# NUC400_v1 register map
File version: 1.0
Registers are 32-bit, read-write, reset 0x0 unless marked. A register's access mark holds for its fields unless they carry their own. Offsets are from the block's base; [hi:lo] are bit positions; {n}, {i} and the like mark numbered series.

## PDMA — PDMA Register Map
Base 0x40008000
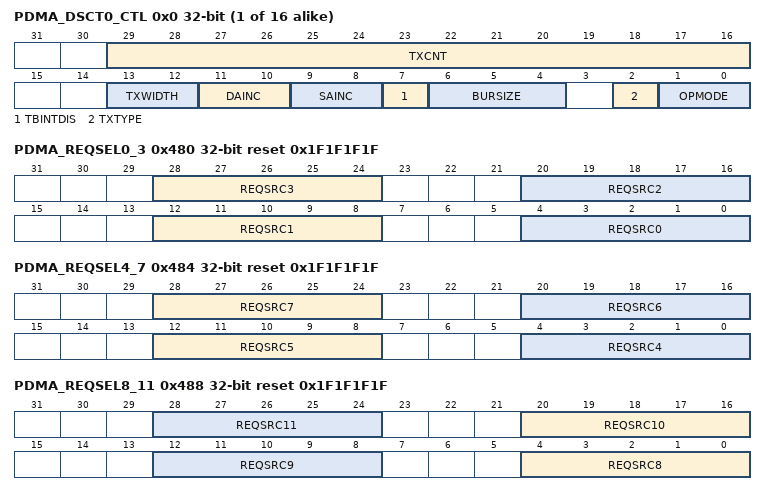
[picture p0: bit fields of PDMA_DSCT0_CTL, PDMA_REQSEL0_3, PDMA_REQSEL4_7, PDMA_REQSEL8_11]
{0x0+0x10*i} PDMA_DSCT{i}_CTL reset not defined (i=0..15) — Descriptor Table Control Register of PDMA Channel {i}
  [29:16] TXCNT — Transfer Count. The TXCNT represents the required number of PDMA transfer, the real transfer count is (TXCNT + 1); The maximum transfer count is 16384, every transfer may be byte, half-word or word that is dependent on TXWIDTH field. Note: When PDMA finish each transfer item, this field will be decrease imminently
  [13:12] TXWIDTH — Transfer Width Selection. This field is used for transfer width. Note: The PDMA transfer source address (DSCTx_ENDSA) and PDMA transfer destination address (DSCTx_ENDDA) should be alignment under the TXWIDTH selection
    0=8 bits for every transfer item; 1=16 bits for every transfer item; 2=32 bits for every transfer item
  [11:10] DAINC — Destination Address Increment. This field is used to set the destination address increment size
    3=No Increment (Fixed Address.)
  [9:8] SAINC — Source Address Increment. This field is used to set the source address increment size
    3=No Increment (Fixed Address.)
  [7] TBINTDIS — Table Interrupt Disable Bit. This field can be used to decide whether to enable table interrupt or not. When with transfer done flag, this bit is only used for scatter-gather mode. If the TBINTDIS bit is enabled when PDMA finishes this task, there will no interrupt generated. However, with the table empty flag, this bit is also useful. If it is set to '1", the TEMPTYF will not be set when this situation has happened.
    0=Table interrupt Enabled; 1=Table interrupt Disabled
  [6:4] BURSIZE — Burst Size. This field is used for peripheral to determine the burst size or used for determine the re-arbitration size. But if in Single Request Type, this field is not useful and only 1 transfer item been transmitted for each transfer
    0=128 transfers; 1=64 transfers; 2=32 transfers; 3=16 transfers; 4=8 transfers; 5=4 transfers; 6=2 transfers; 7=1 transfers
  [2] TXTYPE — Request Type
    0=Burst request type; 1=Single request type
  [1:0] OPMODE — PDMA Operation Mode Selection. Note: Before filling transfer task in the descriptor table, user must check if the descriptor table is complete.
    0=Stop Mode. Channel is stopped or this table is complete, when PDMA finish channel table task, OPMODE will be cleared to stop mode automatically; 1=Basic Mode. The descriptor table only has one task. When this task is finished, the PDMA_INTSTS[x] will be asserted; 2=Scatter-Gather Mode. When operating in this mode, user must give the next descriptor table address in DSCTx_NEXT register; PDMA will ignore this task, and then load the next task to execute
{0x4+0x10*i} PDMA_DSCT{i}_ENDSA reset not defined (i=0..15) — End Source Address Register of PDMA Channel {i}
  [31:0] ENDSA — PDMA Transfer Ending Source Address Bits. This field indicates a 32-bit ending source address of PDMA. Note: If the source start address is 0x2000_0000, the transfer count is 0x100 and the source address increment is word, this field must be filled 0x2000_0400.
{0x8+0x10*i} PDMA_DSCT{i}_ENDDA reset not defined (i=0..15) — End Destination Address Register of PDMA Channel {i}
  [31:0] ENDDA — PDMA Transfer Ending Destination Address Bits. This field indicates a 32-bit ending destination address of PDMA. Note: If the destination start address is 0x2000_0000, the transfer count is 0x100 and the destination address increment is word, this field must be filled 0x2000_0400.
{0xC+0x10*i} PDMA_DSCT{i}_NEXT reset not defined (i=0..15) — Scatter-gather Descriptor Table Offset Address of PDMA Channel {i}
  [15:2] NEXT — PDMA Next Description Table Offset Address Bits. This field indicates the offset of next descriptor table address in system memory. Note1: The next descriptor table address must be word boundary. Note2: The system memory based address is 0x2000_0000 (PDMA_SCATBA), if the next descriptor table is 0x2000_0100, that this field must fill 0x0100. Note3: Before filled transfer task in the description table, user must check if the descriptor table is complete.
{0x100+4i} PDMA_CURSCAT{i} ro (i=0..15) — Current Scatter-gather Descriptor Table Address of PDMA Channel {i}
  [31:0] CURADDR — PDMA External Current Descriptor Address Bits. This field indicates a 32-bit current external descriptor address of PDMA. Note: This field is read only and only used for Scatter-Gather mode to indicate the current external descriptor address.
0x400 PDMA_CHCTL — PDMA Channel Control Register
  [15:0] CHEN — PDMA Channel Enable Control Bit[X]. Set this bit to 1 to enable PDMA[x] operation. Note1: If software stops each PDMA transfer by setting PDMA_STOP register, this bit will be cleared automatically after finishing current transfer. Note2: Software reset (writing 0xFFFF_FFF to PDMA_STOP register) will clear this bit. Note3: If each channel is not set as enabled, each channel cannot be active.
    0=PDMA channel [x] Disabled; 1=PDMA channel [x] Enabled
0x404 PDMA_STOP wo — PDMA Stop Transfer Register
  [15:0] STOP — PDMA Stop Transfer Bit [X]. User can stop the PDMA transfer by software reset (writing all '1' to PDMA_STOP register) or by PDMA_STOP register. The difference between software reset and PDMA_STOP register is when software set software reset, the operation will be stopped imminently that include the on-going transfer and the channel enable bit and request active flag will be cleared to '0'. When software set PDMA_STOP bit, the operation will finish the on-going transfer channel and then clear the channel enable bit and request active flag. Software can poll channel enable bit to know if the on-going transfer is finished. Note1: This field is Write-Only; Note2: Setting all PDMA_STOP bit to "1" will generate software reset to reset internal state machine (the embedded table will not be reset).
    0=No effect; 1=Stop PDMA transfer[x]
0x408 PDMA_SWREQ wo — PDMA Software Request Register
  [11:0] SWREQ — PDMA Software Request Bit [X]. Set this bit to 1 to generate a software request to PDMA [x]. Note1: This field is Write-Only. Software can indicate which channel is on active by reading PDMA_TRGSTS register. Active flag may be triggered by software request or peripheral request. Note2: If user does not enable each PDMA channel, the software request will be ignored.
    0=No effect; 1=Generate a software request
0x40C PDMA_TRGSTS ro — PDMA Request Active Flag Register
  [15:0] REQSTS — PDMA Request Active Flag [X]. This flag indicates whether channel[x] have a request or not. Note1: The request may come from software request (SWREQ) or peripheral request. Note2: When PDMA finishes channel transfer, this bit will be cleared automatically. Note3: Software reset (setting PDMA_STOP to 0xFFFF_FFFF) will clear this bit.
    0=Have no requests; 1=Have a request
0x410 PDMA_PRISET — PDMA Fixed Priority Setting Register
  [15:0] FPRISET — PDMA Fixed Priority Setting Bit[X]. Set this bit to 1 to enable fix priority level. The PDMA channel priority is shown in the following table.
    0=No effect; 1=Set PDMA channel [x] be fixed priority channel
0x414 PDMA_PRICLR wo — PDMA Fixed Priority Clear Register
  [15:0] FPRICLR — PDMA Fix Priority Clear Bit. Set this bit to 1 to clear fixed priority level. Note: This field is Write-Only, and software can indicate the channel priority by reading PDMA_PRISET register.
    0=No effect; 1=Set PDMA channel [x] to be round-robin priority channel
0x418 PDMA_INTEN — PDMA Interrupt Enable Control Register
  [15:0] INTEN — PDMA Interrupt Enable. This field is used for enabling PDMA channel[x] interrupt.
    0=PDMA channel [x] interrupt Disabled; 1=PDMA channel [x] interrupt Enabled
0x41C PDMA_INTSTS — PDMA Interrupt Status Register
  [15:0] ABTIF — PDMA Target Abort Status Flag. This bit indicates which PDMA has target abort error; Note: This field is read only, but software can write 1 to clear it.
    0=No bus ERROR response received; 1=Bus ERROR response received
0x420 PDMA_ABTSTS — PDMA Read/Write Target Abort Flag Register
0x424 PDMA_TDSTS — PDMA Transfer Done Flag Register
  [15:0] TDIF — Transfer Done Flag. This bit indicates which PDMA channel has finished transmission. Note: This field is read only, but software can write 1 to clear.
    0=Not finished yet; 1=PDMA channel has finished transmission
0x428 PDMA_SCATSTS — PDMA Scatter-gather Transfer Done Flag Register
  [15:0] TEMPTYF — Table Empty Flag. This bit indicates which PDMA channel table has finished transmission and the operation mode is Stop mode; Note: This field is read only, but software can write 1 to clear.
    0=Not finished or not in Stop mode; 1=PDMA channel has finished transmission and the operation is Stop mode
0x42C PDMA_TACTSTS ro — PDMA Transfer on Active Flag Register
  [15:0] TXACTF — Transfer On Active Flag. This bit indicates which PDMA channel is on active.
    0=PDMA channel is not finished; 1=PDMA channel is on active
0x43C PDMA_SCATBA reset 0x20000000 — PDMA Scatter-gather Descriptor Table Base Address Register
  [31:16] SCATBA — PDMA Scatter-Gather Descriptor Table Base Address. In Scatter-Gather mode, this is the base address for calculating the next link - list address. The next link address equation is. Note: Only useful in Scatter-Gather mode.
0x480 PDMA_REQSEL0_3 reset 0x1F1F1F1F — PDMA Source Module Select Register 0
  [28:24] REQSRC3 — Channel 3 Selection. This filed defines which peripheral is connected to PDMA channel 3. Software can configure the peripheral setting by REQSRC3. The channel configuration is the same as REQSRC0 field. Please refer to the explanation of REQSRC0.
  [20:16] REQSRC2 — Channel 2 Selection. This filed defines which peripheral is connected to PDMA channel 2. Software can configure the peripheral setting by REQSRC2. The channel configuration is the same as REQSRC0 field. Please refer to the explanation of REQSRC0.
  [12:8] REQSRC1 — Channel 1 Selection. This filed defines which peripheral is connected to PDMA channel 1. Software can configure the peripheral setting by REQSRC1. The channel configuration is the same as REQSRC0 field. Please refer to the explanation of REQSRC0.
  [4:0] REQSRC0 — Channel 0 Selection. This filed defines which peripheral is connected to PDMA channel 0. Software can configure the peripheral by setting REQSRC0.
    {v}=Connect to SPI{v}_TX (v=0..3); {v}=Connect to UART{v-4}_TX (v=4..9); 11=Connect to I2S_TX; 12=Connect to I2S1_TX; {v}=Connect to SPI{v-13}_RX (v=13..16); {v}=Connect to UART{v-17}_RX (v=17..22); 24=Connect to ADC; 25=Connect to I2S_RX; 26=Connect to I2S1_RX
0x484 PDMA_REQSEL4_7 reset 0x1F1F1F1F — PDMA Source Module Select Register 1
  [28:24] REQSRC7 — Channel 7 Selection. This filed defines which peripheral is connected to PDMA channel 7. Software can configure the peripheral setting by REQSRC7. The channel configuration is the same as REQSRC0 field. Please refer to the explanation of REQSRC0.
  [20:16] REQSRC6 — Channel 6 Selection. This filed defines which peripheral is connected to PDMA channel 6. Software can configure the peripheral setting by REQSRC6. The channel configuration is the same as REQSRC0 field. Please refer to the explanation of REQSRC0.
  [12:8] REQSRC5 — Channel 1 Selection. This filed defines which peripheral is connected to PDMA channel 5. Software can configure the peripheral setting by REQSRC5. The channel configuration is the same as REQSRC0 field. Please refer to the explanation of REQSRC0.
  [4:0] REQSRC4 — Channel 0 Selection. This filed defines which peripheral is connected to PDMA channel 4. Software can configure the peripheral setting by REQSRC4. The channel configuration is the same as REQSRC0 field. Please refer to the explanation of REQSRC0.
0x488 PDMA_REQSEL8_11 reset 0x1F1F1F1F — PDMA Source Module Select Register 2
  [8n-60:8n-64] REQSRC{n} (n=8..11) — Channel {n} Selection. This filed defines which peripheral is connected to PDMA channel {n}. Software can configure the peripheral setting by REQSRC{n}. The channel configuration is the same as REQSRC0 field. Please refer to the explanation of REQSRC0.
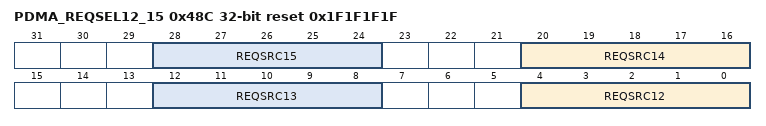
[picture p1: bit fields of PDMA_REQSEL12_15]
0x48C PDMA_REQSEL12_15 reset 0x1F1F1F1F — PDMA Source Module Select Register 3
  [8n-92:8n-96] REQSRC{n} (n=12..15) — Channel {n} Selection. This filed defines which peripheral is connected to PDMA channel {n}. Software can configure the peripheral setting by REQSRC{n}. The channel configuration is the same as REQSRC0 field. Please refer to the explanation of REQSRC0.
